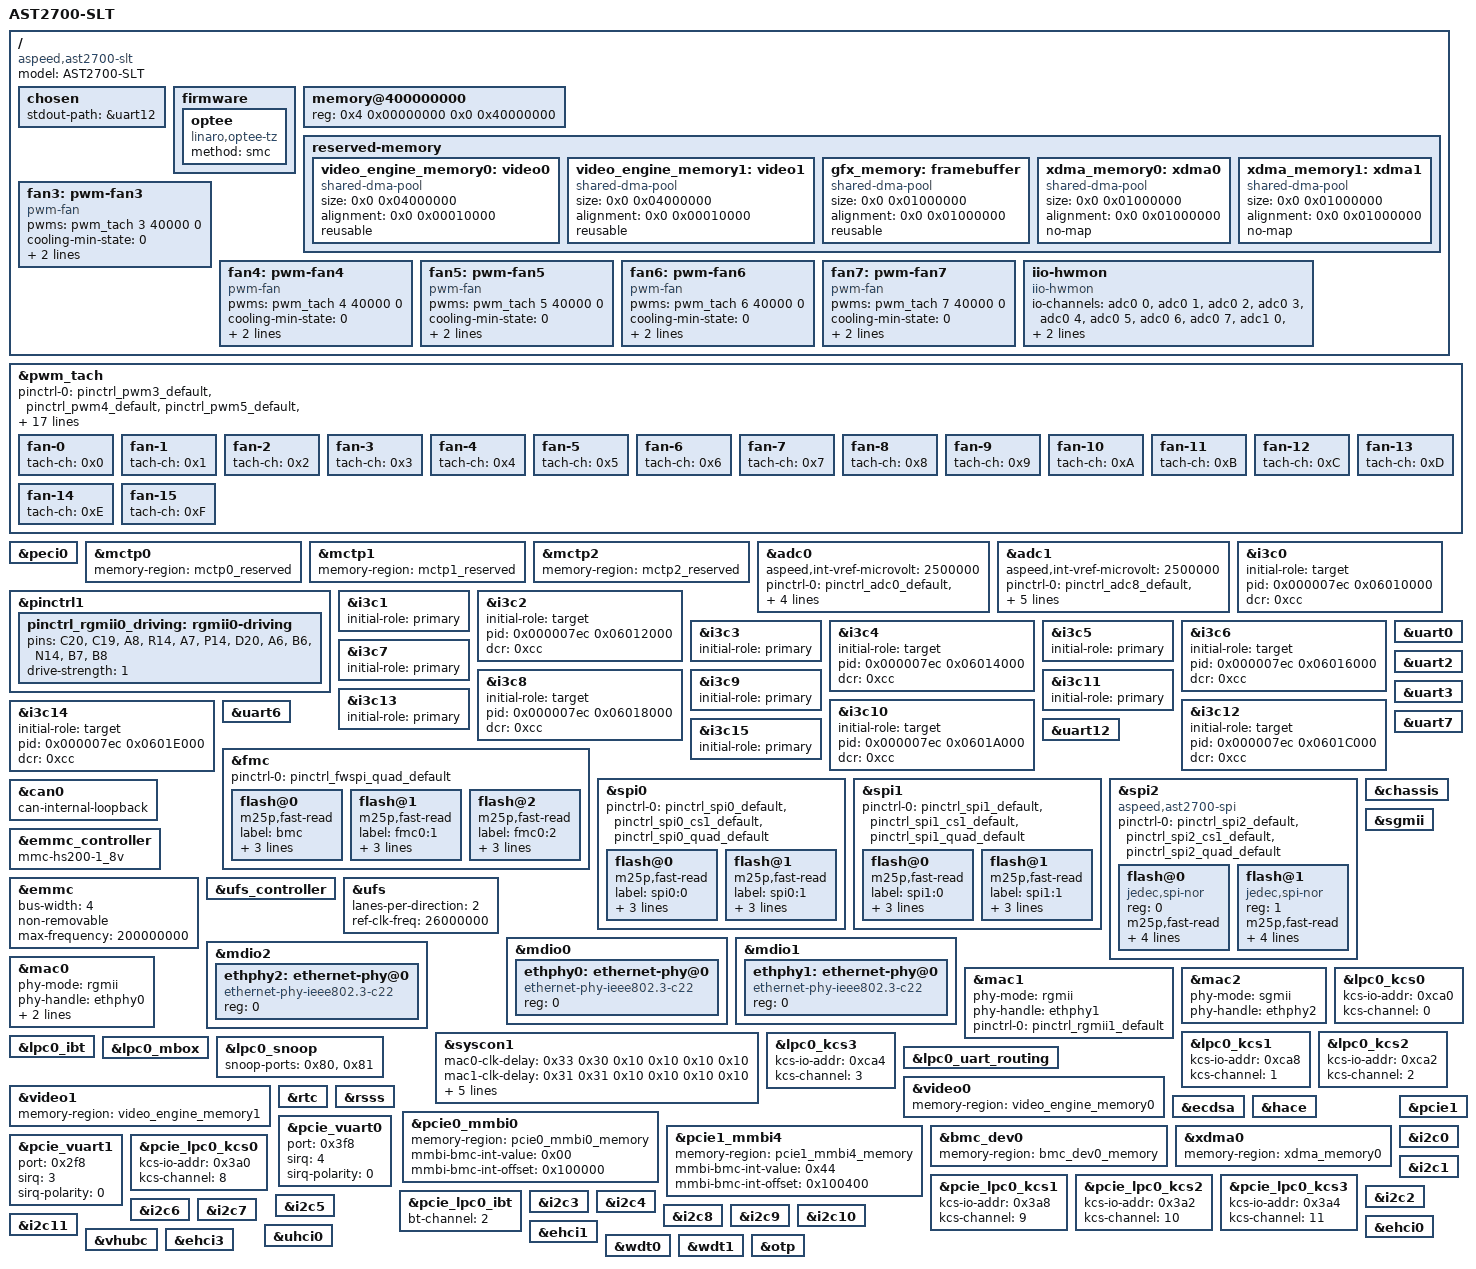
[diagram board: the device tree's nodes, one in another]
// SPDX-License-Identifier: GPL-2.0-or-later

/dts-v1/;

#include "aspeed-g7.dtsi"
#include <dt-bindings/gpio/aspeed-gpio.h>

/ {
	model = "AST2700-SLT";
	compatible = "aspeed,ast2700-slt", "aspeed,ast2700";

	chosen {
		stdout-path = &uart12;
	};

	firmware {
		optee: optee {
			compatible = "linaro,optee-tz";
			method = "smc";
		};
	};

	memory@400000000 {
		device_type = "memory";
		reg = <0x4 0x00000000 0x0 0x40000000>;
	};

	reserved-memory {
		#address-cells = <2>;
		#size-cells = <2>;
		ranges;

		#include "ast2700-reserved-mem.dtsi"

		video_engine_memory0: video0 {
			size = <0x0 0x04000000>;
			alignment = <0x0 0x00010000>;
			compatible = "shared-dma-pool";
			reusable;
		};

		video_engine_memory1: video1{
			size = <0x0 0x04000000>;
			alignment = <0x0 0x00010000>;
			compatible = "shared-dma-pool";
			reusable;
		};

		gfx_memory: framebuffer {
			size = <0x0 0x01000000>;
			alignment = <0x0 0x01000000>;
			compatible = "shared-dma-pool";
			reusable;
		};

		xdma_memory0: xdma0 {
			size = <0x0 0x01000000>;
			alignment = <0x0 0x01000000>;
			compatible = "shared-dma-pool";
			no-map;
		};

		xdma_memory1: xdma1 {
			size = <0x0 0x01000000>;
			alignment = <0x0 0x01000000>;
			compatible = "shared-dma-pool";
			no-map;
		};
	};

	fan3: pwm-fan3 {
		compatible = "pwm-fan";
		pwms = <&pwm_tach 3 40000 0>;	/* Target freq:25 kHz */
		cooling-min-state = <0>;
		cooling-max-state = <3>;
		#cooling-cells = <2>;
		cooling-levels = <0 15 128 255>;
	};

	fan4: pwm-fan4 {
		compatible = "pwm-fan";
		pwms = <&pwm_tach 4 40000 0>;	/* Target freq:25 kHz */
		cooling-min-state = <0>;
		cooling-max-state = <3>;
		#cooling-cells = <2>;
		cooling-levels = <0 15 128 255>;
	};

	fan5: pwm-fan5 {
		compatible = "pwm-fan";
		pwms = <&pwm_tach 5 40000 0>;	/* Target freq:25 kHz */
		cooling-min-state = <0>;
		cooling-max-state = <3>;
		#cooling-cells = <2>;
		cooling-levels = <0 15 128 255>;
	};

	fan6: pwm-fan6 {
		compatible = "pwm-fan";
		pwms = <&pwm_tach 6 40000 0>;	/* Target freq:25 kHz */
		cooling-min-state = <0>;
		cooling-max-state = <3>;
		#cooling-cells = <2>;
		cooling-levels = <0 15 128 255>;
	};

	fan7: pwm-fan7 {
		compatible = "pwm-fan";
		pwms = <&pwm_tach 7 40000 0>;	/* Target freq:25 kHz */
		cooling-min-state = <0>;
		cooling-max-state = <3>;
		#cooling-cells = <2>;
		cooling-levels = <0 15 128 255>;
	};

	iio-hwmon {
		compatible = "iio-hwmon";
		status = "okay";
		io-channels = <&adc0 0>, <&adc0 1>, <&adc0 2>, <&adc0 3>,
				<&adc0 4>, <&adc0 5>, <&adc0 6>, <&adc0 7>,
				<&adc1 0>, <&adc1 1>, <&adc1 2>, <&adc1 3>,
				<&adc1 4>, <&adc1 5>, <&adc1 6>, <&adc1 7>;
	};
};

&pwm_tach {
	status = "okay";
	pinctrl-names = "default";
	pinctrl-0 = <&pinctrl_pwm3_default
		     &pinctrl_pwm4_default &pinctrl_pwm5_default
		     &pinctrl_pwm6_default &pinctrl_pwm7_default
		     &pinctrl_tach0_default &pinctrl_tach1_default
		     &pinctrl_tach2_default &pinctrl_tach3_default
		     &pinctrl_tach4_default &pinctrl_tach5_default
		     &pinctrl_tach6_default &pinctrl_tach7_default
		     &pinctrl_tach8_default &pinctrl_tach9_default
		     &pinctrl_tach10_default &pinctrl_tach11_default
		     &pinctrl_tach12_default &pinctrl_tach13_default
		     &pinctrl_tach14_default &pinctrl_tach15_default>;
	fan-0 {
		tach-ch = /bits/ 8 <0x0>;
	};
	fan-1 {
		tach-ch = /bits/ 8 <0x1>;
	};
	fan-2 {
		tach-ch = /bits/ 8 <0x2>;
	};
	fan-3 {
		tach-ch = /bits/ 8 <0x3>;
	};
	fan-4 {
		tach-ch = /bits/ 8 <0x4>;
	};
	fan-5 {
		tach-ch = /bits/ 8 <0x5>;
	};
	fan-6 {
		tach-ch = /bits/ 8 <0x6>;
	};
	fan-7 {
		tach-ch = /bits/ 8 <0x7>;
	};
	fan-8 {
		tach-ch = /bits/ 8 <0x8>;
	};
	fan-9 {
		tach-ch = /bits/ 8 <0x9>;
	};
	fan-10 {
		tach-ch = /bits/ 8 <0xA>;
	};
	fan-11 {
		tach-ch = /bits/ 8 <0xB>;
	};
	fan-12 {
		tach-ch = /bits/ 8 <0xC>;
	};
	fan-13 {
		tach-ch = /bits/ 8 <0xD>;
	};
	fan-14 {
		tach-ch = /bits/ 8 <0xE>;
	};
	fan-15 {
		tach-ch = /bits/ 8 <0xF>;
	};
};

&peci0 {
	status = "okay";
};

&mctp0 {
	status = "okay";
	memory-region = <&mctp0_reserved>;
};

&mctp1 {
	status = "okay";
	memory-region = <&mctp1_reserved>;
};

&mctp2 {
	status = "okay";
	memory-region = <&mctp2_reserved>;
};

&adc0 {
	aspeed,int-vref-microvolt = <2500000>;
	status = "okay";

	pinctrl-names = "default";
	pinctrl-0 = <&pinctrl_adc0_default &pinctrl_adc1_default
		&pinctrl_adc2_default &pinctrl_adc3_default
		&pinctrl_adc4_default &pinctrl_adc5_default
		&pinctrl_adc6_default &pinctrl_adc7_default>;
};

&adc1 {
	aspeed,int-vref-microvolt = <2500000>;
	status = "okay";

	pinctrl-names = "default";
	pinctrl-0 = <&pinctrl_adc8_default &pinctrl_adc9_default
		&pinctrl_adc10_default &pinctrl_adc11_default
		&pinctrl_adc12_default &pinctrl_adc13_default
		&pinctrl_adc14_default &pinctrl_adc15_default>;
};

&pinctrl1 {
	pinctrl_rgmii0_driving: rgmii0-driving {
		pins = "C20", "C19", "A8", "R14", "A7", "P14",
		       "D20", "A6", "B6", "N14", "B7", "B8";
		drive-strength = <1>;
	};
};

&i3c0 {
	initial-role = "target";
	pid = <0x000007ec 0x06010000>;
	dcr = /bits/ 8 <0xcc>;
	status = "okay";
};

&i3c1 {
	initial-role = "primary";
	status = "okay";
};

&i3c2 {
	initial-role = "target";
	pid = <0x000007ec 0x06012000>;
	dcr = /bits/ 8 <0xcc>;
	status = "okay";
};

&i3c3 {
	initial-role = "primary";
	status = "okay";
};

&i3c4 {
	initial-role = "target";
	pid = <0x000007ec 0x06014000>;
	dcr = /bits/ 8 <0xcc>;
	status = "okay";
};

&i3c5 {
	initial-role = "primary";
	status = "okay";
};

&i3c6 {
	initial-role = "target";
	pid = <0x000007ec 0x06016000>;
	dcr = /bits/ 8 <0xcc>;
	status = "okay";
};

&i3c7 {
	initial-role = "primary";
	status = "okay";
};

&i3c8 {
	initial-role = "target";
	pid = <0x000007ec 0x06018000>;
	dcr = /bits/ 8 <0xcc>;
	status = "okay";
};

&i3c9 {
	initial-role = "primary";
	status = "okay";
};

&i3c10 {
	initial-role = "target";
	pid = <0x000007ec 0x0601A000>;
	dcr = /bits/ 8 <0xcc>;
	status = "okay";
};

&i3c11 {
	initial-role = "primary";
	status = "okay";
};

&i3c12 {
	initial-role = "target";
	pid = <0x000007ec 0x0601C000>;
	dcr = /bits/ 8 <0xcc>;
	status = "okay";
};

&i3c13 {
	initial-role = "primary";
	status = "okay";
};

&i3c14 {
	initial-role = "target";
	pid = <0x000007ec 0x0601E000>;
	dcr = /bits/ 8 <0xcc>;
	status = "okay";
};

&i3c15 {
	initial-role = "primary";
	status = "okay";
};

&uart0 {
	status = "okay";
};

&uart2 {
	status = "okay";
};

&uart3 {
	status = "okay";
};

&uart6 {
	status = "okay";
};

&uart7 {
	status = "okay";
};

&uart12 {
	status = "okay";
};

&fmc {
	status = "okay";
	pinctrl-0 = <&pinctrl_fwspi_quad_default>;
	pinctrl-names = "default";

	flash@0 {
		status = "okay";
		m25p,fast-read;
		label = "bmc";
		spi-max-frequency = <50000000>;
		spi-tx-bus-width = <4>;
		spi-rx-bus-width = <4>;
#include "aspeed-evb-flash-layout-128.dtsi"
	};

	flash@1 {
		status = "okay";
		m25p,fast-read;
		label = "fmc0:1";
		spi-max-frequency = <50000000>;
		spi-tx-bus-width = <4>;
		spi-rx-bus-width = <4>;
	};

	flash@2 {
		status = "okay";
		m25p,fast-read;
		label = "fmc0:2";
		spi-max-frequency = <50000000>;
		spi-tx-bus-width = <4>;
		spi-rx-bus-width = <4>;
	};
};

&spi0 {
	status = "okay";
	pinctrl-0 = <&pinctrl_spi0_default &pinctrl_spi0_cs1_default &pinctrl_spi0_quad_default>;
	pinctrl-names = "default";

	flash@0 {
		status = "okay";
		m25p,fast-read;
		label = "spi0:0";
		spi-max-frequency = <50000000>;
		spi-tx-bus-width = <4>;
		spi-rx-bus-width = <4>;
	};

	flash@1 {
		status = "okay";
		m25p,fast-read;
		label = "spi0:1";
		spi-max-frequency = <50000000>;
		spi-tx-bus-width = <4>;
		spi-rx-bus-width = <4>;
	};
};

&spi1 {
	status = "okay";
	pinctrl-0 = <&pinctrl_spi1_default &pinctrl_spi1_cs1_default &pinctrl_spi1_quad_default>;
	pinctrl-names = "default";

	flash@0 {
		status = "okay";
		m25p,fast-read;
		label = "spi1:0";
		spi-max-frequency = <50000000>;
		spi-tx-bus-width = <4>;
		spi-rx-bus-width = <4>;
	};

	flash@1 {
		status = "okay";
		m25p,fast-read;
		label = "spi1:1";
		spi-max-frequency = <50000000>;
		spi-tx-bus-width = <4>;
		spi-rx-bus-width = <4>;
	};
};

&spi2 {
	compatible = "aspeed,ast2700-spi";
	pinctrl-0 = <&pinctrl_spi2_default &pinctrl_spi2_cs1_default &pinctrl_spi2_quad_default>;
	pinctrl-names = "default";
	status = "okay";

	flash@0 {
		status = "okay";
		reg = < 0 >;
		compatible = "jedec,spi-nor";
		m25p,fast-read;
		label = "spi2:0";
		spi-max-frequency = <50000000>;
		spi-tx-bus-width = <4>;
		spi-rx-bus-width = <4>;
	};

	flash@1 {
		status = "okay";
		reg = < 1 >;
		compatible = "jedec,spi-nor";
		m25p,fast-read;
		label = "spi2:1";
		spi-max-frequency = <50000000>;
		spi-tx-bus-width = <4>;
		spi-rx-bus-width = <4>;
	};
};

&can0 {
	/delete-property/ pinctrl-0;
	/delete-property/ pinctrl-names;

	can-internal-loopback;
	status = "okay";
};

&emmc_controller {
	status = "okay";
	mmc-hs200-1_8v;
};

&emmc {
	status = "okay";
#if 1
	bus-width = <4>;
#else
	bus-width = <8>;
	pinctrl-0 = <&pinctrl_emmc_default
		     &pinctrl_emmcg8_default>;
#endif
	non-removable;
	max-frequency = <200000000>;
};

&ufs_controller {
	status = "okay";
};

&ufs {
	status = "okay";
	lanes-per-direction = <2>;
	ref-clk-freq = <26000000>;
};

&chassis {
	status = "okay";
};

&mdio0 {
	status = "okay";
	#address-cells = <1>;
	#size-cells = <0>;

	ethphy0: ethernet-phy@0 {
		compatible = "ethernet-phy-ieee802.3-c22";
		reg = <0>;
	};
};

&mdio1 {
	status = "okay";
	#address-cells = <1>;
	#size-cells = <0>;

	ethphy1: ethernet-phy@0 {
		compatible = "ethernet-phy-ieee802.3-c22";
		reg = <0>;
	};
};

&mdio2 {
	status = "okay";
	#address-cells = <1>;
	#size-cells = <0>;

	ethphy2: ethernet-phy@0 {
		compatible = "ethernet-phy-ieee802.3-c22";
		reg = <0>;
	};
};

&mac0 {
	status = "okay";

	phy-mode = "rgmii";
	phy-handle = <&ethphy0>;

	pinctrl-names = "default";
	pinctrl-0 = <&pinctrl_rgmii0_default &pinctrl_rgmii0_driving>;
};

&mac1 {
	status = "okay";

	phy-mode = "rgmii";
	phy-handle = <&ethphy1>;

	pinctrl-names = "default";
	pinctrl-0 = <&pinctrl_rgmii1_default>;
};

&sgmii {
	status = "okay";
};

&mac2 {
	status = "okay";

	phy-mode = "sgmii";
	phy-handle = <&ethphy2>;
};

&syscon1 {
	mac0-clk-delay = <0x33 0x30
			  0x10 0x10
			  0x10 0x10>;
	mac1-clk-delay = <0x31 0x31
			  0x10 0x10
			  0x10 0x10>;
	assigned-clocks = <&syscon1 SCU1_CLK_MACHCLK>,
			  <&syscon1 SCU1_CLK_RGMII>,
			  <&syscon1 SCU1_CLK_RMII>;
	assigned-clock-rates = <200000000>, <125000000>, <50000000>;
};

&lpc0_kcs0 {
	status = "okay";
	kcs-io-addr = <0xca0>;
	kcs-channel = <0>;
};

&lpc0_kcs1 {
	status = "okay";
	kcs-io-addr = <0xca8>;
	kcs-channel = <1>;
};

&lpc0_kcs2 {
	status = "okay";
	kcs-io-addr = <0xca2>;
	kcs-channel = <2>;
};

&lpc0_kcs3 {
	status = "okay";
	kcs-io-addr = <0xca4>;
	kcs-channel = <3>;
};

&lpc0_ibt {
	status = "okay";
};

&lpc0_mbox {
	status = "okay";
};

&lpc0_snoop {
	status = "okay";
	snoop-ports = <0x80>, <0x81>;
};

&lpc0_uart_routing {
	status = "okay";
};

&video0 {
	status = "okay";
	memory-region = <&video_engine_memory0>;
};

&video1 {
	status = "okay";
	memory-region = <&video_engine_memory1>;
};

&rtc {
	status = "okay";
};

&rsss {
	status = "okay";
};

&ecdsa {
	status = "okay";
};

&hace {
	status = "okay";
};

&pcie0_mmbi0 {
	status = "okay";
	memory-region = <&pcie0_mmbi0_memory>;

	mmbi-bmc-int-value = /bits/ 8 <0x00>;
	mmbi-bmc-int-offset = <0x100000>;
};

&pcie1_mmbi4 {
	status = "okay";
	memory-region = <&pcie1_mmbi4_memory>;

	mmbi-bmc-int-value = /bits/ 8 <0x44>;
	mmbi-bmc-int-offset = <0x100400>;
};

&bmc_dev0 {
	status = "okay";
	memory-region = <&bmc_dev0_memory>;
};

&xdma0 {
	status = "okay";
	memory-region = <&xdma_memory0>;
};

&pcie_vuart0 {
	port = <0x3f8>;
	sirq = <4>;
	sirq-polarity = <0>;

	status = "okay";
};

&pcie_vuart1 {
	port = <0x2f8>;
	sirq = <3>;
	sirq-polarity = <0>;

	status = "okay";
};

&pcie_lpc0_kcs0 {
	status = "okay";
	kcs-io-addr = <0x3a0>;
	kcs-channel = <8>;
};

&pcie_lpc0_kcs1 {
	status = "okay";
	kcs-io-addr = <0x3a8>;
	kcs-channel = <9>;
};

&pcie_lpc0_kcs2 {
	status = "okay";
	kcs-io-addr = <0x3a2>;
	kcs-channel = <10>;
};

&pcie_lpc0_kcs3 {
	status = "okay";
	kcs-io-addr = <0x3a4>;
	kcs-channel = <11>;
};

&pcie_lpc0_ibt {
	status = "okay";
	bt-channel = <2>;
};

&pcie1 {
	status = "okay";
};

&i2c0 {
	status = "okay";
};

&i2c1 {
	status = "okay";
};

&i2c2 {
	status = "okay";
};

&i2c3 {
	status = "okay";
};

&i2c4 {
	status = "okay";
};

&i2c5 {
	status = "okay";
};

&i2c6 {
	status = "okay";
};

&i2c7 {
	status = "okay";
};

&i2c8 {
	status = "okay";
};

&i2c9 {
	status = "okay";
};

&i2c10 {
	status = "okay";
};

&i2c11 {
	status = "okay";
};

#if 1

&ehci0 {
	status = "okay";
};

&ehci1 {
	status = "okay";
};

&uhci0 {
	status = "okay";
};
#endif

#if 0
&uphy3a {
	status = "okay";
};

&uphy3b {
	status = "okay";
};
#endif

#if 0
&xhci0 {
	status = "okay";
};

&xhci1 {
	status = "okay";
};
#endif

#if 0
&vhuba1 {
	status = "okay";
};

&vhubb1 {
	status = "okay";
};

#endif

#if 0
&vhuba0 {
	status = "okay";
};

&vhubb0 {
	status = "okay";
};
#endif

#if 0
&usb3ahp {
	status = "okay";
};

&usb3bhp {
	status = "okay";
};

&uphy2a {
	status = "okay";
};

&uphy2b {
	status = "okay";
};
#endif

&vhubc {
	status = "okay";
};

&ehci3 {
	status = "okay";
};

&wdt0 {
	status = "okay";
};

&wdt1 {
	status = "okay";
};

&otp {
	status = "okay";
};
